# MCU_ADC0_ECC register map
Vendor: Texas Instruments
Peripheral module from a debugger description file (folder am65x).
Registers are 32-bit, read-write, reset 0x0 unless marked. A register's access mark holds for its fields unless they carry their own. Offsets are as the file gives them; lines under a group give offsets from that group; [hi:lo] are bit positions; {n}, {i} and the like mark numbered series; 'fields as' and 'values as' point back to an identical list; <NAME> marks a mode.

## MCU_ADC0_ECC
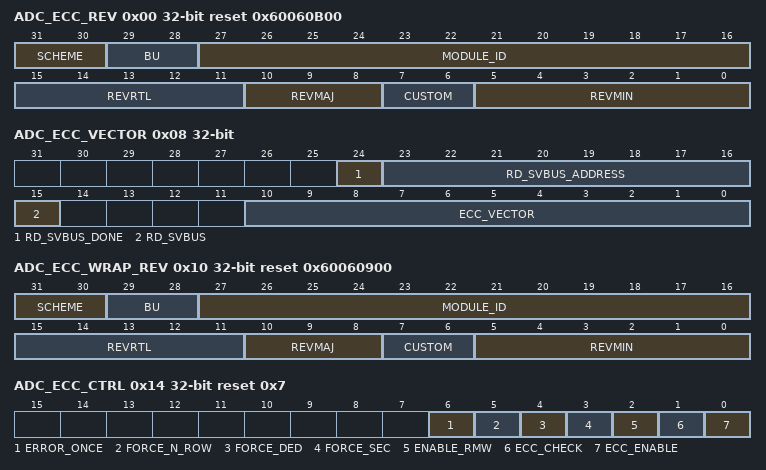
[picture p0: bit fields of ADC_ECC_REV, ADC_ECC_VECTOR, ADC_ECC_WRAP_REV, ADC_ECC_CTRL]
0x00 ADC_ECC_REV ro reset 0x60060B00 — Revision parameters
  [31:30] SCHEME
  [29:28] BU
  [27:16] MODULE_ID
  [15:11] REVRTL — RTL version
  [10:8] REVMAJ — Major version
  [7:6] CUSTOM — Custom version
  [5:0] REVMIN — Minor version
0x08 ADC_ECC_VECTOR access per field — ECC Vector Register
  [24] RD_SVBUS_DONE ro — Status to indicate if read on serial VBUS is complete
  [23:16] RD_SVBUS_ADDRESS rw — Read address
  [15] RD_SVBUS rw — Write 1h = Trigger a read on the serial VBUS
  [10:0] ECC_VECTOR rw — Value written to select the corresponding ECC RAM for
0x0C ADC_ECC_STAT ro reset 0x2 — Misc Status
  [10:0] NUM_RAMS — Indicates the number of RAMS serviced by the ECC aggregator
0x10 ADC_ECC_WRAP_REV ro reset 0x60060900 — Revision parameters
  fields as ADC_ECC_REV
0x14 ADC_ECC_CTRL reset 0x7 — ECC Control Register
  [6] ERROR_ONCE — Force Error only once
  [5] FORCE_N_ROW — Force Error on any RAM read
  [4] FORCE_DED — Force Double Bit Error
  [3] FORCE_SEC — Force Single Bit Error
  [2] ENABLE_RMW
  [1] ECC_CHECK — Enable ECC check
  [0] ECC_ENABLE — Enable ECC
0x18 ADC_ECC_ERR_CTRL1 — ECC Error Control1 Register
  [31:0] ECC_ROW — Row address where single or double-bit error needs to be applied. This is ignored if force_n_row is set
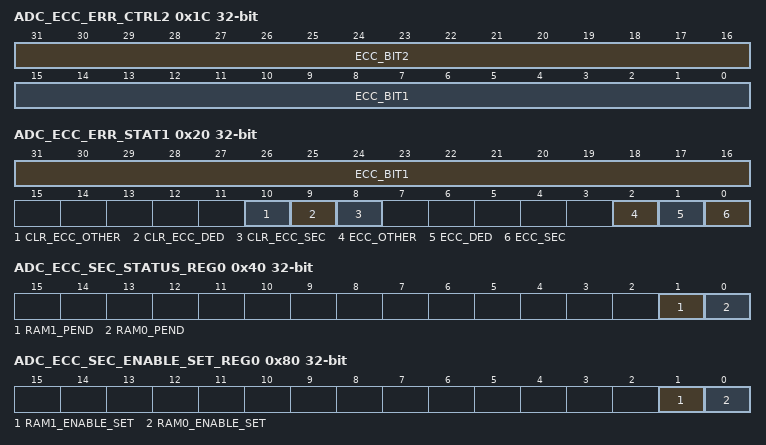
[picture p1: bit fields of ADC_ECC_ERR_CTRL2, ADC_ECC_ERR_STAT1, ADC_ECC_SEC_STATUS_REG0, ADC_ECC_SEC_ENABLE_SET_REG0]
0x1C ADC_ECC_ERR_CTRL2 — ECC Error Control2 Register
  [31:16] ECC_BIT2 — Data bit that needs to be flipped if double bit error needs to be forced
  [15:0] ECC_BIT1 — Data bit that needs to be flipped when force_sec is set
0x20 ADC_ECC_ERR_STAT1 access per field — ECC Error Status1 Register
  [31:16] ECC_BIT1 ro — Data bit that corresponds to the single-bit error
  [10] CLR_ECC_OTHER rw — Clear other Error Status
  [9] CLR_ECC_DED rw — Clear Double Bit Error Status
  [8] CLR_ECC_SEC rw — Clear Single Bit Error Status
  [2] ECC_OTHER rw — Successive single-bit errors have occurred while a writeback is still pending, Level interrupt
  [1] ECC_DED rw — Level Double Bit Error Status
  [0] ECC_SEC rw — Level Single Bit Error Status
0x24 ADC_ECC_ERR_STAT2 ro — ECC Error Status1 Register
  [31:0] ECC_ROW — Row address where the single or double-bit error has occurred
0x3C ADC_ECC_SEC_EOI_REG — Register
  [0] EOI_WR
0x40 ADC_ECC_SEC_STATUS_REG0 — Interrupt Status Register 0
  [1] RAM1_PEND — Interrupt Pending Status for ram1_pend
  [0] RAM0_PEND — Interrupt Pending Status for ram0_pend
0x80 ADC_ECC_SEC_ENABLE_SET_REG0 — Interrupt Enable Set Register 0
  [1] RAM1_ENABLE_SET — Interrupt Enable Set Register for ram1_pend
  [0] RAM0_ENABLE_SET — Interrupt Enable Set Register for ram0_pend
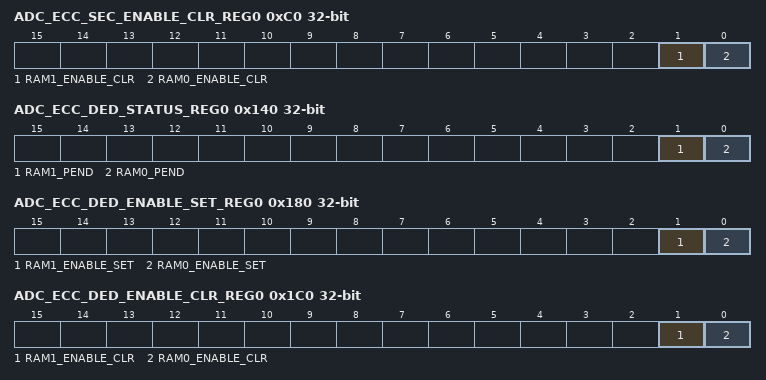
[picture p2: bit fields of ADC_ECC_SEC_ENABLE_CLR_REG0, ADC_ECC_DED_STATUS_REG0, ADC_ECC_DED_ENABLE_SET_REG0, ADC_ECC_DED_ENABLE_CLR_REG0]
0xC0 ADC_ECC_SEC_ENABLE_CLR_REG0 — Interrupt Enable Clear Register 0
  [1] RAM1_ENABLE_CLR — Interrupt Enable Clear Register for ram1_pend
  [0] RAM0_ENABLE_CLR — Interrupt Enable Clear Register for ram0_pend
0x13C ADC_ECC_DED_EOI_REG — Register
  [0] EOI_WR
0x140 ADC_ECC_DED_STATUS_REG0 — Interrupt Status Register 0
  fields as ADC_ECC_SEC_STATUS_REG0
0x180 ADC_ECC_DED_ENABLE_SET_REG0 — Interrupt Enable Set Register 0
  fields as ADC_ECC_SEC_ENABLE_SET_REG0
0x1C0 ADC_ECC_DED_ENABLE_CLR_REG0 — Interrupt Enable Clear Register 0
  fields as ADC_ECC_SEC_ENABLE_CLR_REG0
